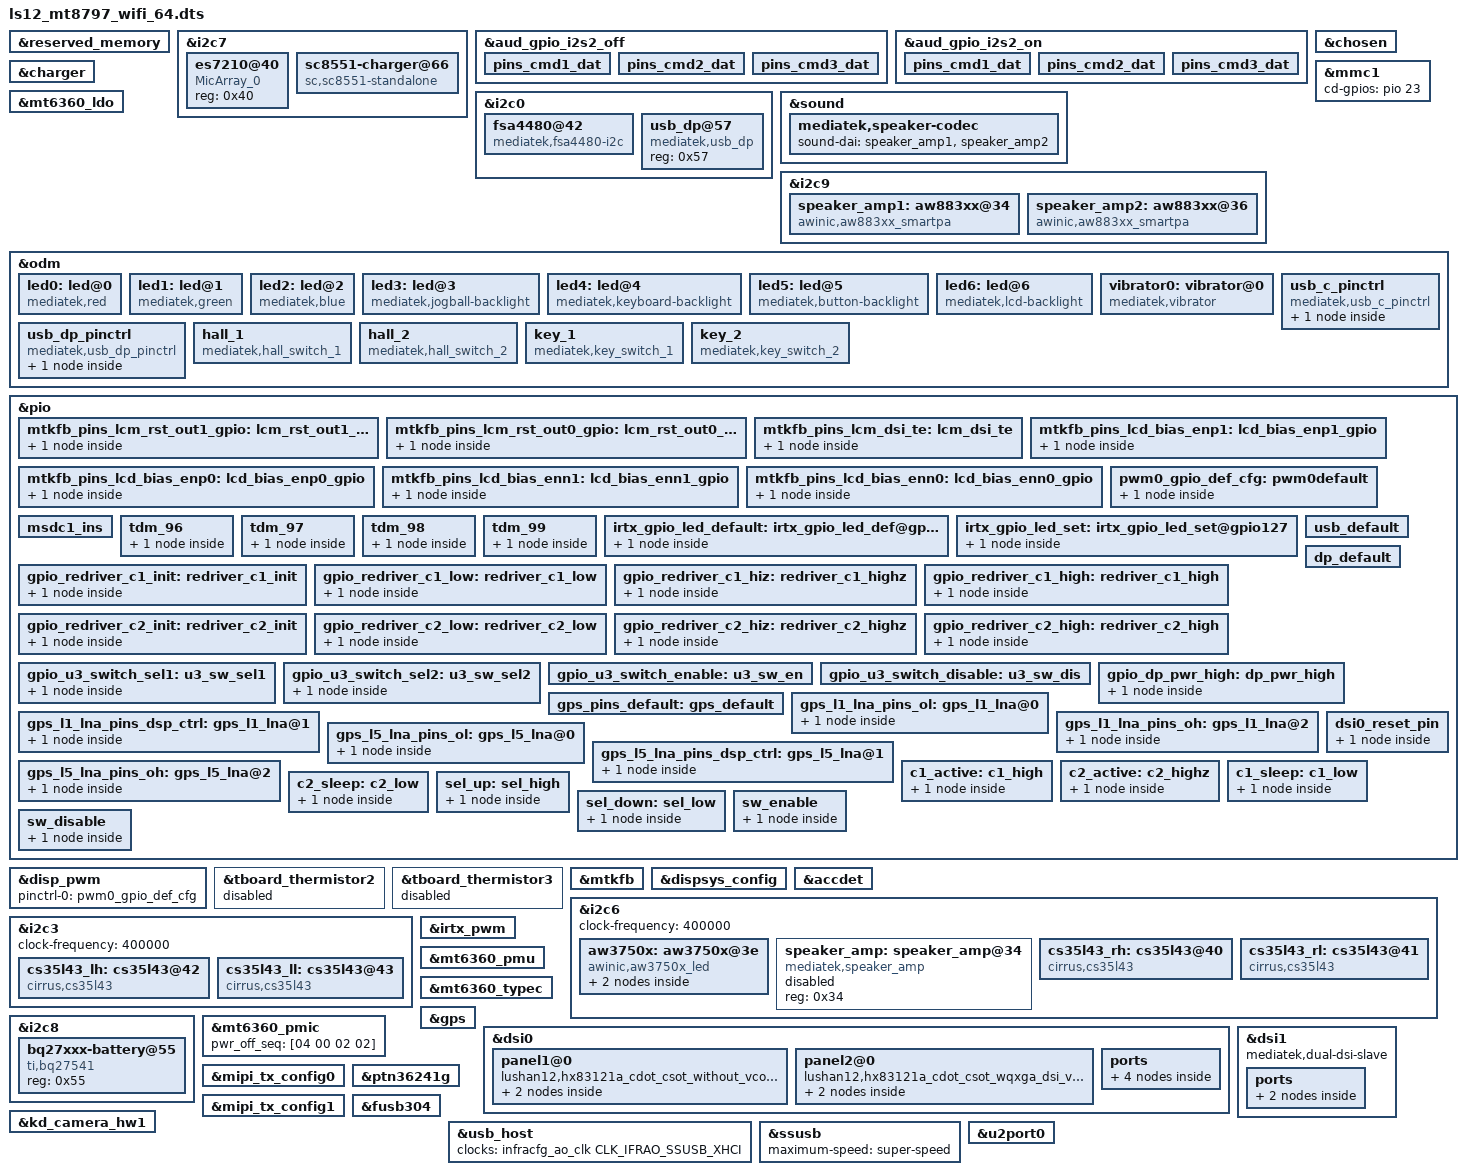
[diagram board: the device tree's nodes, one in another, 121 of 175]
// SPDX-License-Identifier: GPL-2.0
/*
 * Copyright (c) 2019 MediaTek Inc.
 *
 */
/dts-v1/;
/plugin/;
#include <dt-bindings/interrupt-controller/irq.h>
#include <dt-bindings/interrupt-controller/arm-gic.h>
#include <dt-bindings/spmi/spmi.h>
#include <dt-bindings/pinctrl/mt6885-pinfunc.h>
#include <dt-bindings/clock/mt6893-clk.h>

&reserved_memory {
};
//Begin modify by lanying.he for es7210 adc bringup
&i2c7 {
	status = "okay";
	es7210@40 {
		compatible = "MicArray_0";
		reg = <0x40>;
		status = "okay";
	};
};
&aud_gpio_i2s2_off {
		pins_cmd1_dat {
			pinmux = <PINMUX_GPIO110__FUNC_GPIO110>;
			input-enable;
			bias-pull-down;
		};
		pins_cmd2_dat {
			pinmux = <PINMUX_GPIO111__FUNC_GPIO111>;
			input-enable;
			bias-pull-down;
		};
		pins_cmd3_dat {
			pinmux = <PINMUX_GPIO112__FUNC_GPIO112>;
			input-enable;
			bias-pull-down;
		};
};
&aud_gpio_i2s2_on {
		pins_cmd1_dat {
			pinmux = <PINMUX_GPIO110__FUNC_I2S2_BCK>;
			input-schmitt-enable;
			bias-disable;
		};
		pins_cmd2_dat {
			pinmux = <PINMUX_GPIO111__FUNC_I2S2_LRCK>;
			input-schmitt-enable;
			bias-disable;
		};
		pins_cmd3_dat {
			pinmux = <PINMUX_GPIO112__FUNC_I2S2_DI>;
			input-schmitt-enable;
			bias-disable;
		};
};
//End modify by lanying.he for es7210 adc bringup
//Begin modify by lanying.he for ocp96011 typec headset
&i2c0 {
/*Type-C Analog Audio Switch : OCP96011*/
fsa4480@42 {
     		compatible = "mediatek,fsa4480-i2c";
      		reg = <0x42>;
     		hs-det-gpio = <&pio 101 0x0>;
			mic-gpio = <&pio 44 0x0>;
     		status = "okay";
     	};
//begin add by wenhaodeng for task LUSHAN-102 on 20230803
	usb_dp@57 {
		compatible = "mediatek,usb_dp";
		reg = <0x57>;
		status = "okay";
	};
//end add by wenhaodeng for task LUSHAN-102 on 20230803	
};
//End modify by lanying.he for ocp96011 typec headset
//Begin added by lanying.he for aw883xx bringup on 2023/7/11
&sound {
		mediatek,speaker-codec {
			sound-dai = <&speaker_amp1>,<&speaker_amp2>;
		};
};
&i2c9 {
 	speaker_amp1:aw883xx@34 {
 		compatible = "awinic,aw883xx_smartpa";
 		reg = <0x34>;
 		#sound-dai-cells = <0>;
 		reset-gpio = <&pio 19 0>;
 		sound-channel = <0>;
 		re-min = <1000>;
 		re-max= <40000>;
 		status = "okay";
 	};
 	speaker_amp2:aw883xx@36{
 		compatible = "awinic,aw883xx_smartpa";
 		reg = <0x36>;
 		#sound-dai-cells = <0>;
 		reset-gpio = <&pio 19 0>;
 		sound-channel = <1>;
 		re-min = <1000>;
 		re-max= <40000>;
 		status = "okay";
 	};
};
//End added by lanying.he for aw883xx bringup
/* chosen */
&chosen {

	atag,videolfb-fb_base_l = <0x7e020000>;
	atag,videolfb-fb_base_h = <0x0>;
	atag,videolfb-islcmfound = <1>;
	atag,videolfb-islcm_inited = <0>;
	atag,videolfb-fps= <6000>;
	atag,videolfb-vramSize= <0x1be0000>;
	atag,videolfb-lcmname=
		"nt35595_fhd_dsi_cmd_truly_nt50358_drv";
};

&charger {
	battery_cv = <4400000>;
	max_charger_voltage = <11000000>;
};

&mmc1 {
	cd-gpios = <&pio 23 0>;
};

&mt6360_ldo {
	sdcard_hlact = <0>;
	sdcard_det_en = <1>;
};

&odm {
	led0:led@0 {
		compatible = "mediatek,red";
		led_mode = <0>;
		data = <1>;
		pwm_config = <0 0 0 0 0>;
	};
	led1:led@1 {
		compatible = "mediatek,green";
		led_mode = <0>;
		data = <1>;
		pwm_config = <0 0 0 0 0>;
	};
	led2:led@2 {
		compatible = "mediatek,blue";
		led_mode = <0>;
		data = <1>;
		pwm_config = <0 0 0 0 0>;
	};
	led3:led@3 {
		compatible = "mediatek,jogball-backlight";
		led_mode = <0>;
		data = <1>;
		pwm_config = <0 0 0 0 0>;
	};
	led4:led@4 {
		compatible = "mediatek,keyboard-backlight";
		led_mode = <0>;
		data = <1>;
		pwm_config = <0 0 0 0 0>;
	};
	led5:led@5 {
		compatible = "mediatek,button-backlight";
		led_mode = <0>;
		data = <1>;
		pwm_config = <0 0 0 0 0>;
	};
	led6:led@6 {
		compatible = "mediatek,lcd-backlight";
		led_mode = <5>;
		data = <1>;
		pwm_config = <0 1 0 0 0>;
	};
	vibrator0:vibrator@0 {
		compatible = "mediatek,vibrator";
		vib_timer = <25>;
		vib_limit = <9>;
		vib_vol= <9>;
	};
	usb_c_pinctrl:usb_c_pinctrl {
		compatible = "mediatek,usb_c_pinctrl";
	};
	usb_dp_pinctrl:usb_dp_pinctrl {
		compatible = "mediatek,usb_dp_pinctrl";
	};
//Begin  by xiakang.chen for hallkey on 2023/8/1
	hall_1:hall_1 {
	   compatible = "mediatek,hall_switch_1";
       hall-gpio = <&pio 22 0x0>;
	   interrupt-parent = <0x48>;
	   interrupts = <0x16 0x08 0x16 0x00>;
       linux,hall = <0x15>;
    };
    hall_2:hall_2  {
	   compatible = "mediatek,hall_switch_2";
       hall-gpio = <&pio 23 0x0>;
	   interrupt-parent = <0x48>;
	   interrupts = <0x17 0x08 0x17 0x00>;
       linux,hall = <0x16>;
    };
	key_1:key_1 {
	   compatible = "mediatek,key_switch_1";
       key-gpio = <&pio 5 0x0>;
	   interrupt-parent = <0x48>;
	   interrupts = <0x05 0x01 0x05 0x00>;
       linux,keycode_down = <0x74>;
	   status = "okay";
    };
    key_2:key_2  {
	   compatible = "mediatek,key_switch_2";
      key-gpio = <&pio 9 0x0>;
	  interrupt-parent = <0x48>;
	   interrupts = <0x09 0x01 0x09 0x00>;
       linux,keycode_down = <0x74>;
	   status = "okay";
    };
//end  by xiakang.chen for hallkey on 2023/8/1
	
};

/* DISPSYS GPIO standardization */
&pio {
	mtkfb_pins_lcm_rst_out1_gpio: lcm_rst_out1_gpio {
		pins_cmd_dat {
			pinmux = <PINMUX_GPIO42__FUNC_GPIO42>;
			slew-rate = <1>;
			output-high;
		};
	};

	mtkfb_pins_lcm_rst_out0_gpio: lcm_rst_out0_gpio {
		pins_cmd_dat {
			pinmux = <PINMUX_GPIO42__FUNC_GPIO42>;
			slew-rate = <1>;
			output-low;
		};
	};

	mtkfb_pins_lcm_dsi_te: lcm_dsi_te {
		pins_cmd_dat {
			pinmux = <PINMUX_GPIO41__FUNC_DSI_TE>;
		};
	};
	
//Begin by yongzhuo for LUSHAN-3 on 2023.07.01
	mtkfb_pins_lcd_bias_enp1: lcd_bias_enp1_gpio {
		pins_cmd_dat {
			pinmux = <PINMUX_GPIO29__FUNC_GPIO29>;
			slew-rate = <1>;
			output-high;
		};
	};

	mtkfb_pins_lcd_bias_enp0: lcd_bias_enp0_gpio {
		pins_cmd_dat {
			pinmux = <PINMUX_GPIO29__FUNC_GPIO29>;
			slew-rate = <1>;
			output-low;
		};
	};

	mtkfb_pins_lcd_bias_enn1: lcd_bias_enn1_gpio {
		pins_cmd_dat {
			pinmux = <PINMUX_GPIO28__FUNC_GPIO28>;
			slew-rate = <1>;
			output-high;
		};
	};

	mtkfb_pins_lcd_bias_enn0: lcd_bias_enn0_gpio {
		pins_cmd_dat {
			pinmux = <PINMUX_GPIO28__FUNC_GPIO28>;
			slew-rate = <1>;
			output-low;
		};
	};
        pwm0_gpio_def_cfg: pwm0default {
            pins_cmd_dat {
                pinmux = <PINMUX_GPIO40__FUNC_DISP_PWM>;
            };
        };
//End by yongzhuo for LUSHAN-3 on 2023.07.01

	msdc1_ins: msdc1_ins{
	};
};

//Begin by yongzhuo for LUSHAN-3 on 2023.07.01
&disp_pwm {
    pinctrl-names = "default";
    pinctrl-0 = <&pwm0_gpio_def_cfg>;
    status = "okay";
};
//End by yongzhuo for LUSHAN-3 on 2023.07.01


&tboard_thermistor2 {
	status = "disabled";
};

&tboard_thermistor3 {
	status = "disabled";
};

&mtkfb {
	pinctrl-names =
		"lcm_rst_out1_gpio", "lcm_rst_out0_gpio",
		"mode_te_te",
//Begin by yongzhuo for LUSHAN-3 on 2023.07.01
		"lcd_bias_enp1_gpio", "lcd_bias_enp0_gpio",
		"lcd_bias_enn1_gpio", "lcd_bias_enn0_gpio";
	pinctrl-0 = <&mtkfb_pins_lcm_rst_out1_gpio>;
	pinctrl-1 = <&mtkfb_pins_lcm_rst_out0_gpio>;
	pinctrl-2 = <&mtkfb_pins_lcm_dsi_te>;
	pinctrl-3 = <&mtkfb_pins_lcd_bias_enp1>;
	pinctrl-4 = <&mtkfb_pins_lcd_bias_enp0>;
	pinctrl-5 = <&mtkfb_pins_lcd_bias_enn1>;
	pinctrl-6 = <&mtkfb_pins_lcd_bias_enn0>;
//End by yongzhuo for LUSHAN-3 on 2023.07.01
	status = "okay";
};

&dispsys_config {
	pinctrl-names =
		"lcm_rst_out1_gpio", "lcm_rst_out0_gpio",
		"mode_te_te";
	pinctrl-0 = <&mtkfb_pins_lcm_rst_out1_gpio>;
	pinctrl-1 = <&mtkfb_pins_lcm_rst_out0_gpio>;
	pinctrl-2 = <&mtkfb_pins_lcm_dsi_te>;
	status = "okay";
};
/* DISPSYS GPIO standardization end */

/* accdet start */
&accdet {
	/* accdet micbias voltage: 0x09:2.85v 0x08:2.8v 0x07,
	 * 2.7v;0x05,2.5v;0x02,1.9v
	 */
	accdet-mic-vol = <8>;
	/* accdet pwm_width, pwm_thresh, fall_delay, rise_delay
	 * debounce0, debounce1, debounce3, debounce4
	 * eint pwm_width, eint pwm_thresh
	 * eint deb(debounce0, debounce1, debounce2, debounce3), inv_debounce
	 */
	headset-mode-setting = <0x500 0x500 1 0x1f0
				0x800 0x800 0x20 0x44
				0x4 0x1
				0x5 0x3 0x3 0x5 0xe>;
	accdet-plugout-debounce = <1>;
	/*1:ACC mode, 2:low cost without in bias, 6:low cost with in bias*/
	accdet-mic-mode = <2>;
	/*0--MD_MAX--UP_MAX--DW_MAX*/
	headset-three-key-threshold = <0 80 220 400>;
	headset-three-key-threshold-CDD = <0 121 192 600>;
	/*0--MD_MAX--VOICE_MAX--UP_MAX--DW_MAX*/
	headset-four-key-threshold = <0 58 121 192 400>;

	/* select VTH to 2v and 500k, use internal resitance */
	eint_use_ext_res = <0>;
	status = "okay";
};
/* accdet end */

&pio {

	tdm_96: tdm_96{
			pins_cmd_dat {
			pinmux = <PINMUX_GPIO96__FUNC_TDM_LRCK>;
			drive-strength=<7>;
		};
	};
	tdm_97: tdm_97{
			pins_cmd_dat {
			pinmux = <PINMUX_GPIO97__FUNC_TDM_BCK>;
			drive-strength=<7>;
		};
	};
	tdm_98: tdm_98{
			pins_cmd_dat {
			pinmux = <PINMUX_GPIO98__FUNC_TDM_MCK>;
			drive-strength=<7>;
		};
	};
	tdm_99: tdm_99{
			pins_cmd_dat {
			pinmux = <PINMUX_GPIO99__FUNC_TDM_DATA0>;
			drive-strength=<7>;
		};
	};
};

&i2c6 {
	clock-frequency = <400000>;
	status = "okay";
//Begin by yongzhuo for LUSHAN-3 on 2023.07.01
	aw3750x: aw3750x@3e {
		compatible = "awinic,aw3750x_led";
		aw3750x_gpio_ctrl = <0>;
		reg = <0x3e>;
		limit = <0x172>;
		outp = <0x0e>;
		outn = <0x0e>;

		enp {
			label = "outp";
			regulator-name = "outp";
			regulator-min-microvolt = <4000000>;
			regulator-max-microvolt = <6000000>;
		};

		enn {
			label = "outn";
			regulator-name = "outn";
			regulator-min-microvolt = <4000000>;
			regulator-max-microvolt = <6000000>;
		};
	};
//End by yongzhuo for LUSHAN-3 on 2023.07.01
	speaker_amp: speaker_amp@34 {
		compatible = "mediatek,speaker_amp";
		#sound-dai-cells = <0>;
		reg = <0x34>;
		status = "disable";
	};
	cs35l43_rh: cs35l43@40 {
		#sound-dai-cells = <1>;
		compatible = "cirrus,cs35l43";
		reg = <0x40>;
		/* NFC header pin 16 */

		interrupt-parent = <&pio>;
		interrupts = <18 IRQ_TYPE_LEVEL_LOW 18 0>;
		reset-gpios = <&pio 126 0>;
		//pinctrl-names = "default";
		//pinctrl-0 = <&amp_rh_irq>,<&amp_rh_reset>;
		status = "okay";
	};
	cs35l43_rl: cs35l43@41 {
		compatible = "cirrus,cs35l43";
		reg = <0x41>;
		interrupt-parent = <&pio>;
		interrupts = <14 IRQ_TYPE_LEVEL_LOW 14 0>;
		reset-gpios = <&pio 127 0>;
		//pinctrl-names = "default";
		//pinctrl-0 = <&amp_rl_irq>,<&amp_rl_reset>;
		status = "okay";
	};
};

&i2c3 {
	clock-frequency = <400000>;
	status = "okay";
	cs35l43_lh: cs35l43@42 {
		compatible = "cirrus,cs35l43";
		reg = <0x42>;

		reset-gpios = <&pio 28 0>;
		interrupt-parent = <&pio>;
		interrupts = <13 IRQ_TYPE_LEVEL_LOW 13 0>;
		//pinctrl-names = "default";
		//pinctrl-0 = <&amp_lh_irq>, <&amp_lh_reset>;
		status = "okay";
	};
	cs35l43_ll: cs35l43@43 {
		compatible = "cirrus,cs35l43";
		reg = <0x43>;

		reset-gpios = <&pio 30 0>;
		interrupt-parent = <&pio>;
		interrupts = <5 IRQ_TYPE_LEVEL_LOW 5 0>;
		//pinctrl-names = "default";
		//pinctrl-0 = <&amp_ll_irq>, <&amp_ll_reset>;
		status = "okay";
	};
};
//Begin deleted by lanying.he for aw88394 bringup
/*
&sound {
	mtk_spk_i2s_out = <1>;
	mtk_spk_i2s_in = <2>;
	pinctrl-names="default";
	pinctrl-0 = <&tdm_96>, <&tdm_97>, <&tdm_98>,<&tdm_99>;
	cirrus,prince-max-devs = <4>;
	cirrus,prince-devs = <&cs35l43_rh>, <&cs35l43_rl>, <&cs35l43_lh>, <&cs35l43_ll>;
	cirrus,prince-dev-prefix = "SPK1", "SPK2", "SPK3", "SPK4";
};
*/
//End deleted by lanying.he for aw88394 bringup
/* IRTX GPIO Start */
&irtx_pwm {
	pinctrl-names = "irtx_gpio_led_default", "irtx_gpio_led_set";
	pinctrl-0 = <&irtx_gpio_led_default>;
	pinctrl-1 = <&irtx_gpio_led_set>;
	status = "okay";
};

&i2c7 {
	sc8551-charger@66{
		compatible = "sc,sc8551-standalone";
		reg = <0x66>;
		sc,sc8551,interrupt_gpios = <&pio 11 0>;
		sc,sc8551,bat-therm-disable = <0>;
		sc,sc8551,bus-therm-disable = <0>;

		sc,sc8551,bat-ovp-threshold = <4500>;
		sc,sc8551,bat-ovp-alarm-threshold = <4450>;
		sc,sc8551,bat-ocp-threshold = <6500>;
		sc,sc8551,bat-ocp-alarm-threshold = <6200>;

		sc,sc8551,bus-ovp-threshold = <12000>;
		sc,sc8551,bus-ovp-alarm-threshold = <11000>;
		sc,sc8551,bus-ocp-threshold = <3500>;
		sc,sc8551,bus-ocp-alarm-threshold = <3200>;

		sc,sc8551,bat-ucp-alarm-threshold = <2000>;

		sc,sc8551,bat-therm-threshold = <0x15>;
		sc,sc8551,bus-therm-threshold = <0x15>;
		sc,sc8551,die-therm-threshold = <125>;

		sc,sc8551,ac-ovp-threshold = <17>;
		sc,sc8551,sense-resistor-mohm = <5>;
	};
};

&i2c8 {
	bq27xxx-battery@55 {
		compatible = "ti,bq27541";
		reg = <0x55>;
		status = "okay";
	};
};

&pio {
	/* IRTX GPIO Settings -Start */
	/* default: GPIO0, output, high */
	irtx_gpio_led_default:irtx_gpio_led_def@gpio127 {
		pins_cmd_dat {
			pinmux = <PINMUX_GPIO127__FUNC_GPIO127>;
			slew-rate = <1>;
			bias-disable;
			output-low;
			input-schmitt-enable = <0>;
		};
	};

	irtx_gpio_led_set:irtx_gpio_led_set@gpio127 {
		pins_cmd_dat {
			pinmux = <PINMUX_GPIO127__FUNC_PWM_3>;
			slew-rate = <1>;
			output-high;
		};
	};
}; /* IRTX GPIO Settings -End */

/* FINGERPRINT start */
/*&spi1 {
	#address-cells = <1>;
	#size-cells = <0>;
	tee-only;
	fingerprint@0 {
		compatible = "goodix,goodix-fp";
		reg = <0>;
		spi-max-frequency = <8000000>;
		netlink-event = <30>;
		vfp-supply = <&mt_pmic_vfp_ldo_reg>;
		power-type = <1>;
		status = "okay";
	};
};

&goodix_fp {
	pinctrl-names = "default", "reset_high", "reset_low", "eint_init";
	pinctrl-0 = <&fingerprint_default>;
	pinctrl-1 = <&fingerprint_reset_high>;
	pinctrl-2 = <&fingerprint_reset_low>;
	pinctrl-3 = <&fingerprint_eint_init>;
	interrupt-parent = <&pio>;
	interrupts = <15 IRQ_TYPE_EDGE_RISING 15 0>;
	status = "okay";
};

&pio {
	fingerprint_default: state_default {
	};
	fingerprint_reset_high: state_reset_high {
		pins_cmd_dat {
			pinmux = <PINMUX_GPIO14__FUNC_GPIO14>;
			slew-rate = <1>;
			output-high;
		};
	};
	fingerprint_reset_low: state_reset_low {
		pins_cmd_dat {
			pinmux = <PINMUX_GPIO14__FUNC_GPIO14>;
			slew-rate = <1>;
			output-low;
		};
	};
	fingerprint_eint_init: state_eint_init {
		pins_cmd_dat {
			pinmux = <PINMUX_GPIO15__FUNC_GPIO15>;
			slew-rate = <0>;
			bias-pull-up = <MTK_PUPD_SET_R1R0_10>;
			input-schmitt-enable;
		};
	};
};*/
/* FINGERPRINT end */

&mt6360_pmu {
	mt6360,intr_gpio_num = <24>; // direct defined GPIO num //
	mt6360,intr_gpio = <&pio 24 0x0>;
};

&mt6360_pmic  {
	pwr_off_seq = [04 00 02 02];
};

&mt6360_typec {
	mt6360pd,intr_gpio_num = <25>; /* direct defined GPIO num */
	mt6360pd,intr_gpio = <&pio 25 0x0>;
};

/* USB SWITCH GPIO start */
&pio {
	usb_default: usb_default {
	};

	gpio_redriver_c1_init: redriver_c1_init {
		pins_cmd_dat {
			pinmux = <PINMUX_GPIO191__FUNC_GPIO191>;
			slew-rate = <1>;
			output-low;
		};
	};

	gpio_redriver_c1_low: redriver_c1_low {
		pins_cmd_dat {
			pinmux = <PINMUX_GPIO191__FUNC_GPIO191>;
			slew-rate = <1>;
			output-low;
		};
	};

	gpio_redriver_c1_hiz: redriver_c1_highz {
		pins_cmd_dat {
			pinmux = <PINMUX_GPIO191__FUNC_GPIO191>;
			slew-rate= <0>;
			bias-disable;
		};
	};

	gpio_redriver_c1_high: redriver_c1_high {
		pins_cmd_dat {
			pinmux = <PINMUX_GPIO191__FUNC_GPIO191>;
			slew-rate = <1>;
			output-high;
		};
	};

	gpio_redriver_c2_init: redriver_c2_init {
		pins_cmd_dat {
			//pinmux = <PINMUX_GPIO189__FUNC_GPIO189>;
			slew-rate = <1>;
			output-low;
		};
	};

	gpio_redriver_c2_low: redriver_c2_low {
		pins_cmd_dat {
			//pinmux = <PINMUX_GPIO189__FUNC_GPIO189>;
			slew-rate = <1>;
			output-low;
		};
	};

	gpio_redriver_c2_hiz: redriver_c2_highz {
		pins_cmd_dat {
			//pinmux = <PINMUX_GPIO189__FUNC_GPIO189>;
			slew-rate= <0>;
			bias-disable;
		};
	};

	gpio_redriver_c2_high: redriver_c2_high {
		pins_cmd_dat {
			//pinmux = <PINMUX_GPIO189__FUNC_GPIO189>;
			slew-rate = <1>;
			output-high;
		};
	};

	gpio_u3_switch_sel1: u3_sw_sel1 {
		pins_cmd_dat {
			//pinmux = <PINMUX_GPIO111__FUNC_GPIO111>;
			slew-rate = <1>;
			output-low;
		};
	};

	gpio_u3_switch_sel2: u3_sw_sel2 {
		pins_cmd_dat {
			//pinmux = <PINMUX_GPIO111__FUNC_GPIO111>;
			slew-rate = <1>;
			output-high;
		};
	};

	gpio_u3_switch_enable: u3_sw_en {
	};

	gpio_u3_switch_disable: u3_sw_dis {
	};
};

&usb_c_pinctrl {
	pinctrl-names = "usb_default",
		"redrv_c1_init",
		"redrv_c1_low",
		"redrv_c1_hiz",
		"redrv_c1_high",
		"redrv_c2_init",
		"redrv_c2_low",
		"redrv_c2_hiz",
		"redrv_c2_high",
		"switch_sel1",
		"switch_sel2",
		"switch_enable",
		"switch_disable";

	pinctrl-0 = <&usb_default>;
	pinctrl-1 = <&gpio_redriver_c1_init>;
	pinctrl-2 = <&gpio_redriver_c1_low>;
	pinctrl-3 = <&gpio_redriver_c1_hiz>;
	pinctrl-4 = <&gpio_redriver_c1_high>;
	pinctrl-5 = <&gpio_redriver_c2_init>;
	pinctrl-6 = <&gpio_redriver_c2_low>;
	pinctrl-7 = <&gpio_redriver_c2_hiz>;
	pinctrl-8 = <&gpio_redriver_c2_high>;
	pinctrl-9 = <&gpio_u3_switch_sel1>;
	pinctrl-10 = <&gpio_u3_switch_sel2>;
	pinctrl-11 = <&gpio_u3_switch_enable>;
	pinctrl-12 = <&gpio_u3_switch_disable>;
	status = "okay";

	usb_switch-data {
		en_pin_num = <0>;
		en_pin_val = <0>;
		//sel_pin_num = <111>;
		sel_pin_val = <1>;
		c1_pin_num = <191>;
		c1_pin_val = <2>;
		//c2_pin_num = <189>;
		c2_pin_val = <1>;
	};
};
/* USB SWITCH GPIO end */

/* USB DP SWITCH GPIO start */
//begin add by wenhaodeng for task LUSHAN-102 on 20230803
&pio {
	dp_default: dp_default {
	};

	gpio_dp_pwr_high: dp_pwr_high {
		pins_cmd_dat {
			pinmux = <PINMUX_GPIO145__FUNC_GPIO145>;
			slew-rate = <1>;
			output-high;
		};
	};

//	gpio_ext_pwr_high: dp_ext_pwr_high {
//		pins_cmd_dat {
//			pinmux = <PINMUX_GPIO130__FUNC_GPIO130>;
//			slew-rate = <1>;
//			output-low;
//		};
//	};
};

&usb_dp_pinctrl {
	pinctrl-names = "dp_default",
		"dp_pwr_high",
		"dp_ext_pwr_high";

	pinctrl-0 = <&dp_default>;
	pinctrl-1 = <&gpio_dp_pwr_high>;
//	pinctrl-2 = <&gpio_ext_pwr_high>;
	status = "okay";

	usb_dp-data {
		platform = "phone";
	};
};
//end add by wenhaodeng for task LUSHAN-102 on 20230803
/* USB DP SWITCH GPIO end */

/* GPS GPIO standardization start */
&pio {
	gps_pins_default: gps_default {
	};

	gps_l1_lna_pins_ol: gps_l1_lna@0 {
		pins_cmd_dat {
			pinmux = <PINMUX_GPIO162__FUNC_GPIO162>;
			output-low;
		};
	};
	gps_l1_lna_pins_dsp_ctrl: gps_l1_lna@1 {
		pins_cmd_dat {
			pinmux = <PINMUX_GPIO162__FUNC_GPS_L1_ELNA_EN>;
		};
	};
	gps_l1_lna_pins_oh: gps_l1_lna@2 {
		pins_cmd_dat {
			pinmux = <PINMUX_GPIO162__FUNC_GPIO162>;
			output-high;
		};
	};

	gps_l5_lna_pins_ol: gps_l5_lna@0 {
		pins_cmd_dat {
			pinmux = <PINMUX_GPIO163__FUNC_GPIO163>;
			output-low;
		};
	};
	gps_l5_lna_pins_dsp_ctrl: gps_l5_lna@1 {
		pins_cmd_dat {
			pinmux = <PINMUX_GPIO163__FUNC_GPS_L5_ELNA_EN>;
		};
	};
	gps_l5_lna_pins_oh: gps_l5_lna@2 {
		pins_cmd_dat {
			pinmux = <PINMUX_GPIO163__FUNC_GPIO163>;
			output-high;
		};
	};
};

&gps {
	pinctrl-names = "default",
		"gps_l1_lna_disable",
		"gps_l1_lna_dsp_ctrl",
		"gps_l1_lna_enable",
		"gps_l5_lna_disable",
		"gps_l5_lna_dsp_ctrl",
		"gps_l5_lna_enable";
	pinctrl-0 = <&gps_pins_default>;
	pinctrl-1 = <&gps_l1_lna_pins_ol>;
	pinctrl-2 = <&gps_l1_lna_pins_dsp_ctrl>;
	pinctrl-3 = <&gps_l1_lna_pins_oh>;
	pinctrl-4 = <&gps_l5_lna_pins_ol>;
	pinctrl-5 = <&gps_l5_lna_pins_dsp_ctrl>;
	pinctrl-6 = <&gps_l5_lna_pins_oh>;
	status = "okay";
};
/* GPS GPIO standardization end */

&dsi0 {
	status = "okay";
	#address-cells = <1>;
	#size-cells = <0>;
	panel1@0 {
		compatible = "lushan12,hx83121a_cdot_csot_without_vcom_wqxga_dsi_vdo";
		reg = <0>;
		reset-gpios = <&pio 42 0>; /* LCM reset */
		bias-gpios = <&pio 29 0>, <&pio 28 0>; /* +-5.5V */
		vddi_18-gpios = <&pio 27 0>;
		vdd_12-gpios = <&pio 127 0>;
		tp_reset-gpios = <&pio 14 0>;
		tct_esd_te_master = <&pio 41 0>;
		tct_esd_te_slave = <&pio 7 0>;
		pinctrl-names = "default";
		port {
			panel_in1: endpoint {
				remote-endpoint = <&dsi_out>;
			};
		};
	};
	panel2@0 {
		compatible = "lushan12,hx83121a_cdot_csot_wqxga_dsi_vdo";
		reg = <1>;
		reset-gpios = <&pio 42 0>;
		bias-gpios = <&pio 29 0>, <&pio 28 0>;
		vddi_18-gpios = <&pio 27 0>;
		vdd_12-gpios = <&pio 127 0>;
		tp_reset-gpios = <&pio 14 0>;
		tct_esd_te_master = <&pio 41 0>;
		tct_esd_te_slave = <&pio 7 0>;
		pinctrl-names = "default";
		port {
			panel_in2: endpoint {
				remote-endpoint = <&dsi_out>;
			};
		};
	};
	ports {
		port@0 {
			reg = <0>;
			dsi_out: endpoint {
				remote-endpoint = <&panel_in1>;
			};
		};
		port@1 {
			reg = <1>;
			master_out: endpoint {
				remote-endpoint = <&slave_in>;
			};
		};
	};
};

&dsi1 {
	mediatek,dual-dsi-slave;
	status = "okay";

	ports {
		port@1 {
			reg = <1>;
			slave_in: endpoint {
				remote-endpoint = <&master_out>;
			};
		};
	};
};

&pio {
	dsi0_reset_pin: dsi0_reset_pin {
		pins_cmd_dat {
			pinmux = <PINMUX_GPIO42__FUNC_GPIO42>;
			output-high;
		};
	};
};

&mipi_tx_config0 {
	status = "okay";
};

&mipi_tx_config1 {
	status = "okay";
};

/* CAMERA specify sensor */
&kd_camera_hw1 {
	cam2_enable_sensor = "s5k3m5sx_mipi_raw s5kjd1_mipi_raw";
	cam4_enable_sensor = "imx481_mipi_raw";
};
/* CAMERA specify sensor end */

/* usb typec mux */
&pio {
	c1_active: c1_high {
		pins_cmd_dat {
			pinmux = <PINMUX_GPIO113__FUNC_GPIO113>;
			output-high;
		};
	};

	c2_active: c2_highz {
		pins_cmd_dat {
			//pinmux = <PINMUX_GPIO112__FUNC_GPIO112>;
			input-enable;
			bias-disable;
		};
	};

	c1_sleep: c1_low {
		pins_cmd_dat {
			pinmux = <PINMUX_GPIO113__FUNC_GPIO113>;
			output-low;
		};
	};

	c2_sleep: c2_low {
		pins_cmd_dat {
			//pinmux = <PINMUX_GPIO112__FUNC_GPIO112>;
			output-low;
		};
	};

	sel_up: sel_high {
		pins_cmd_dat {
			//pinmux = <PINMUX_GPIO111__FUNC_GPIO111>;
			output-high;
		};
	};

	sel_down: sel_low {
		pins_cmd_dat {
			//pinmux = <PINMUX_GPIO111__FUNC_GPIO111>;
			output-low;
		};
	};

	sw_enable: sw_enable {
		pins_cmd_dat {
			//pinmux = <PINMUX_GPIO110__FUNC_GPIO110>;
			output-low;
		};
	};

	sw_disable: sw_disable {
		pins_cmd_dat {
			//pinmux = <PINMUX_GPIO110__FUNC_GPIO110>;
			output-low;
		};
	};
};

&ptn36241g {
	pinctrl-names = "c1_active", "c1_sleep",
		"c2_active", "c2_sleep";
	pinctrl-0 = <&c1_active>;
	pinctrl-1 = <&c1_sleep>;
	pinctrl-2 = <&c2_active>;
	pinctrl-3 = <&c2_sleep>;
	status = "okay";
};

&fusb304 {
	pinctrl-names = "sel_up", "sel_down",
		"enable", "disable";
	pinctrl-0 = <&sel_up>;
	pinctrl-1 = <&sel_down>;
	pinctrl-2 = <&sw_enable>;
	pinctrl-3 = <&sw_disable>;
	status = "okay";
};

&usb_host {
	clocks = <&infracfg_ao_clk CLK_IFRAO_SSUSB_XHCI>;
	clock-names = "sys_ck";
};

&ssusb {
	maximum-speed = "super-speed";
};

/* Add-start by baiwei.peng for usb2.0 eye diagram on 2023/08/02 */
&u2port0 {
	mediatek,eye-vrt = <6>; /* 0~7 */
	mediatek,eye-term = <6>; /* 0~7 */
	mediatek,eye-rev6 = <3>; /* 0~3 */
	mediatek,eye-disc = <14>; /* 0-15 */
};
/* Add-end by baiwei.peng for usb2.0 eye diagram on 2023/08/02 */

#include "mediatek/bat_setting/lushan/ls_charge.dtsi"
#include "mediatek/bat_setting/lushan/ls12_battery_prop.dtsi"
//Begin by yongzhuo for LUSHAN-4 on 2023.07.03
#include "mediatek/cust_lushan12_touch_spi.dtsi"
//End by yongzhuo for LUSHAN-4 on 2023.07.03
#include "mediatek/cust_tb8797p2_ls12_camera.dtsi"
#include <ls12_mt8797_wifi_64/cust.dtsi>
/*End of this file, DO NOT ADD ANYTHING HERE*/
